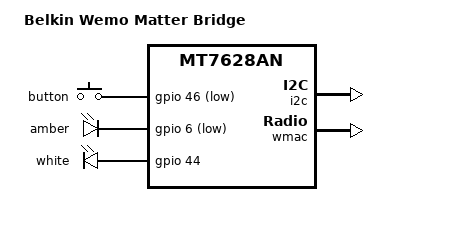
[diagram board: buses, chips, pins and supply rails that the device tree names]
// SPDX-License-Identifier: GPL-2.0-or-later OR MIT
/dts-v1/;

#include "mt7628an.dtsi"

#include <dt-bindings/gpio/gpio.h>
#include <dt-bindings/input/input.h>

/ {
	compatible = "belkin,wemo-matter-bridge", "mediatek,mt7628an-soc";
	model = "Belkin Wemo Matter Bridge";

	aliases {
		led-boot = &led_white;
		led-failsafe = &led_amber;
		led-running = &led_white;
		led-upgrade = &led_amber;
		label-mac-device = &ethernet;
	};

	keys {
		compatible = "gpio-keys-polled";
		poll-interval = <50>;
		autorepeat;

		button {
			label = "button";
			gpios = <&gpio 46 GPIO_ACTIVE_LOW>;
			linux,code = <BTN_0>;
		};
	};

	leds {
		compatible = "gpio-leds";

		led_amber: amber {
			label = "amber";
			gpios = <&gpio 6 GPIO_ACTIVE_LOW>;
			default-state = "off";
			linux,default-trigger = "none";
		};

		led_white: white {
			label = "white";
			gpios = <&gpio 44 GPIO_ACTIVE_HIGH>;
			default-state = "on";
			linux,default-trigger = "timer";
		};
	};
};

&state_default {
	gpio {
		groups = "wdt", "wled_an", "spi cs1", "uart1";
		function = "gpio";
	};
};

&i2c {
	status = "okay";
};

&wmac {
	status = "okay";

	nvmem-cells = <&eeprom_factory_0>;
	nvmem-cell-names = "eeprom";
};

&ethernet {
	nvmem-cells = <&macaddr_factory_28>;
	nvmem-cell-names = "mac-address";
};
